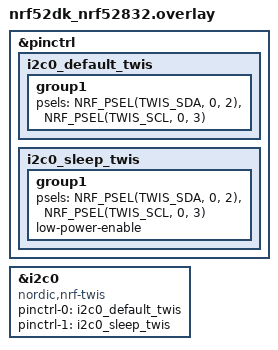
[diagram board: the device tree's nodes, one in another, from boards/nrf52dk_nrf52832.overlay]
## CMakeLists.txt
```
# SPDX-License-Identifier: Apache-2.0
#
# Copyright (c) Centro de Inovacao EDGE - 2026

cmake_minimum_required(VERSION 3.20.0)
find_package(Zephyr REQUIRED HINTS $ENV{ZEPHYR_BASE})
project(zbook_i2c_target_fixture)

target_sources(app PRIVATE src/main.c)
```

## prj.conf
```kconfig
CONFIG_I2C=y
CONFIG_I2C_TARGET=y
CONFIG_GPIO=y

CONFIG_I2C_TARGET_BUFFER_MODE=y

CONFIG_USE_SEGGER_RTT=y
CONFIG_RTT_CONSOLE=y
CONFIG_UART_CONSOLE=n
```

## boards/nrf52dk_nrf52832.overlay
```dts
/*
 * Turns i2c0 into an I2C *target* (slave), answering at 0x50 -- matching
 * zbook-sdk's CONFIG_ZBOOK_TEST_I2C_EXTERNAL_ADDR default. The target
 * itself (address + callbacks) is registered in src/main.c via
 * i2c_target_register() directly against this bus device -- no
 * devicetree child node/driver needed. Using P0.02 (SDA) / P0.03 (SCL)
 * here instead of the DK's default Arduino I2C pins (P0.26/P0.27) --
 * both free header pins, not claimed by any on-board LED/button/UART --
 * purely to make wiring/troubleshooting easier; the TWIS peripheral
 * isn't tied to any particular pin pair, any two GPIOs work via pinctrl.
 *
 * Wire this bus to the zbook's GPIO header (H1, I2C_SDA/I2C_SCL) with a
 * common ground: nRF52 P0.02 <-> zbook I2C_SDA, nRF52 P0.03 <-> zbook
 * I2C_SCL. i2c0 normally runs as a TWI/TWIM *controller* -- overriding its
 * compatible to "nordic,nrf-twis" switches it to the TWIS *peripheral*
 * personality instead (a controller and a target can't share one instance
 * at the same time).
 */

&pinctrl {
	i2c0_default_twis: i2c0_default_twis {
		group1 {
			psels = <NRF_PSEL(TWIS_SDA, 0, 2)>,
				<NRF_PSEL(TWIS_SCL, 0, 3)>;
		};
	};

	i2c0_sleep_twis: i2c0_sleep_twis {
		group1 {
			psels = <NRF_PSEL(TWIS_SDA, 0, 2)>,
				<NRF_PSEL(TWIS_SCL, 0, 3)>;
			low-power-enable;
		};
	};
};

&i2c0 {
	compatible = "nordic,nrf-twis";
	status = "okay";
	pinctrl-0 = <&i2c0_default_twis>;
	pinctrl-1 = <&i2c0_sleep_twis>;
	pinctrl-names = "default", "sleep";
};
```

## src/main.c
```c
/*******************************************************************
 * @file main.c
 *
 * @brief I2C target fixture for validating zbook_i2c's external GPIO header.
 * @author Matheus Macário dos Santos (matheus.macario@edge.ufal.br)
 * @version 0.1
 * @date 18/09/2026
 *
 * @copyright Copyright (c) Centro de Inovacao EDGE - 2026
 *
 *******************************************************************/

#include <zephyr/kernel.h>
#include <zephyr/sys/printk.h>
#include <zephyr/drivers/i2c.h>
#include <zephyr/drivers/gpio.h>

#define TARGET_ADDR 0x50

static const struct device *const i2c_dev = DEVICE_DT_GET(DT_NODELABEL(i2c0));

/* Lit once the target is actually registered -- a glance at the board
 * confirms the fixture is up without needing RTT/serial hooked up.
 */
static const struct gpio_dt_spec led0 = GPIO_DT_SPEC_GET(DT_ALIAS(led0), gpios);

/* Fixed reply byte for read probes -- the zbook test only checks that the
 * read succeeds (ACK), never the value, but a recognizable byte makes it
 * obvious in a logic analyzer capture which side sent it.
 */
static uint8_t tx_byte = 0xA5;
static uint8_t rx_buf[32];

static int target_buf_read_requested(struct i2c_target_config *config, uint8_t **ptr,
				      uint32_t *len)
{
	ARG_UNUSED(config);

	printk("I2C TARGET: address matched, master reading -- sending 0x%02x\n", tx_byte);
	*ptr = &tx_byte;
	*len = sizeof(tx_byte);
	return 0;
}

static void target_buf_write_received(struct i2c_target_config *config, uint8_t *ptr,
				       uint32_t len)
{
	ARG_UNUSED(config);

	printk("I2C TARGET: address matched, master wrote %u byte(s):", len);
	for (uint32_t i = 0; i < len && i < sizeof(rx_buf); i++) {
		printk(" 0x%02x", ptr[i]);
	}
	printk("\n");
}

/* The nRF TWIS driver (drivers/i2c/i2c_nrfx_twis.c) is DMA/buffer-based and
 * only ever calls the buf_* callbacks below -- write_requested/
 * read_requested/read_processed/stop are never invoked by this driver, so
 * they're omitted rather than left as dead code.
 */
static const struct i2c_target_callbacks target_callbacks = {
	.buf_read_requested = target_buf_read_requested,
	.buf_write_received = target_buf_write_received,
};

static struct i2c_target_config target_cfg = {
	.address = TARGET_ADDR,
	.callbacks = &target_callbacks,
};

int main(void)
{
	printk("zbook i2c target fixture (custom target, addr 0x%02x)\n", TARGET_ADDR);

	if (!device_is_ready(i2c_dev)) {
		printk("i2c0 device not ready\n");
		return 0;
	}

	if (i2c_target_register(i2c_dev, &target_cfg) < 0) {
		printk("failed to register i2c target\n");
		return 0;
	}

	printk("i2c target registered at 0x%02x -- staying up\n", TARGET_ADDR);

	if (gpio_is_ready_dt(&led0)) {
		gpio_pin_configure_dt(&led0, GPIO_OUTPUT_ACTIVE);
	}

	return 0;
}
```
